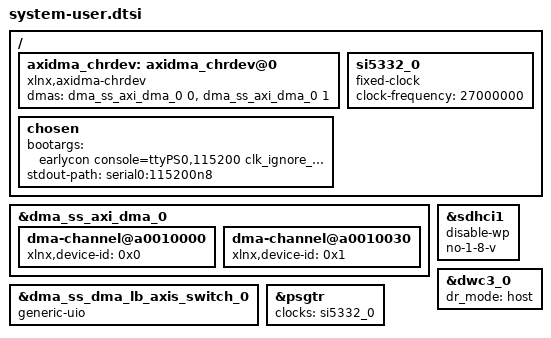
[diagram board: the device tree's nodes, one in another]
/include/ "system-conf.dtsi"
/ {
	axidma_chrdev: axidma_chrdev@0 {
	    compatible = "xlnx,axidma-chrdev";
	    dmas = <&dma_ss_axi_dma_0 0 &dma_ss_axi_dma_0 1>;
	    dma-names = "tx_channel", "rx_channel";
	};
	chosen {
		bootargs = " earlycon console=ttyPS0,115200 clk_ignore_unused root=/dev/mmcblk1p2 rw rootwait uio_pdrv_genirq.of_id=generic-uio";
		stdout-path = "serial0:115200n8";
	};
	si5332_0: si5332_0{ /* clk2_dp */
		compatible = "fixed-clock";
		#clock-cells = <0>;
		clock-frequency = <27000000>;
	};
};

&dma_ss_axi_dma_0 {
	dma-channel@a0010000 { //check address from pl.dtsi
		xlnx,device-id = <0x0>;
	};
	dma-channel@a0010030 { //check address from pl.dtsi
		xlnx,device-id = <0x1>;
	};
};

&dma_ss_dma_lb_axis_switch_0 {
	compatible = "generic-uio";
};

&sdhci1 {
	disable-wp;
	no-1-8-v;
};

&dwc3_0 {
    dr_mode = "host";
};

&psgtr {
	status = "okay";
	/* dp */
	clocks = <&si5332_0>;
	clock-names = "ref2";
};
